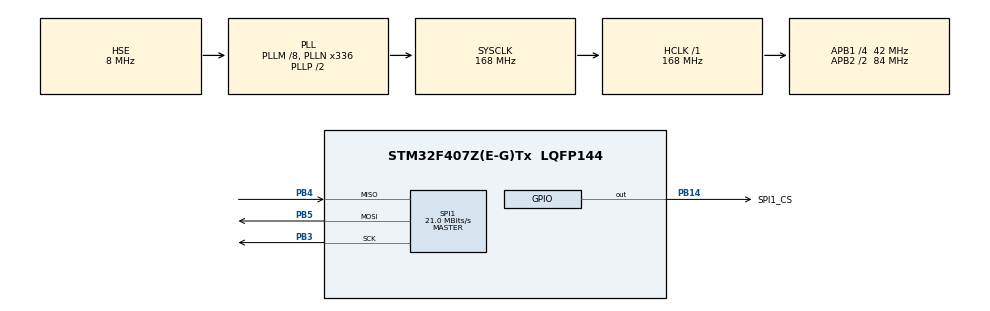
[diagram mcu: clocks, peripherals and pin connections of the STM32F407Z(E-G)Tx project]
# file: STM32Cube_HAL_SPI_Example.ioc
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Dma.Request0=SPI1_RX
Dma.Request1=SPI1_TX
Dma.SPI1_RX.0.Direction=DMA_PERIPH_TO_MEMORY
Dma.SPI1_RX.0.FIFOMode=DMA_FIFOMODE_DISABLE
Dma.SPI1_RX.0.Instance=DMA2_Stream0
Dma.SPI1_RX.0.MemDataAlignment=DMA_MDATAALIGN_BYTE
Dma.SPI1_RX.0.MemInc=DMA_MINC_ENABLE
Dma.SPI1_RX.0.Mode=DMA_NORMAL
Dma.SPI1_RX.0.PeriphDataAlignment=DMA_PDATAALIGN_BYTE
Dma.SPI1_RX.0.PeriphInc=DMA_PINC_DISABLE
Dma.SPI1_RX.0.Priority=DMA_PRIORITY_MEDIUM
Dma.SPI1_TX.1.Direction=DMA_MEMORY_TO_PERIPH
Dma.SPI1_TX.1.FIFOMode=DMA_FIFOMODE_DISABLE
Dma.SPI1_TX.1.Instance=DMA2_Stream3
Dma.SPI1_TX.1.MemDataAlignment=DMA_MDATAALIGN_BYTE
Dma.SPI1_TX.1.MemInc=DMA_MINC_ENABLE
Dma.SPI1_TX.1.Mode=DMA_NORMAL
Dma.SPI1_TX.1.PeriphDataAlignment=DMA_PDATAALIGN_BYTE
Dma.SPI1_TX.1.PeriphInc=DMA_PINC_DISABLE
Dma.SPI1_TX.1.Priority=DMA_PRIORITY_MEDIUM
Mcu.Family=STM32F4
Mcu.Name=STM32F407Z(E-G)Tx
Mcu.Package=LQFP144
NVIC.DMA2_Stream0_IRQn=true\:0\:0\:false\:true\:true\:2\:false
NVIC.DMA2_Stream3_IRQn=true\:0\:0\:false\:true\:true\:3\:false
NVIC.PriorityGroup=NVIC_PRIORITYGROUP_4
NVIC.SPI1_IRQn=true\:0\:0\:false\:true\:true\:1\:true
PB14.GPIO_Label=SPI1_CS
PB14.GPIO_PuPd=GPIO_PULLUP
PB14.GPIO_Speed=GPIO_SPEED_FREQ_VERY_HIGH
PB14.PinState=GPIO_PIN_SET
PB14.Signal=GPIO_Output
PB3.Mode=Full_Duplex_Master
PB3.Signal=SPI1_SCK
PB4.Mode=Full_Duplex_Master
PB4.Signal=SPI1_MISO
PB5.Mode=Full_Duplex_Master
PB5.Signal=SPI1_MOSI
PH0-OSC_IN.Mode=HSE-External-Oscillator
PH0-OSC_IN.Signal=RCC_OSC_IN
PH1-OSC_OUT.Mode=HSE-External-Oscillator
PH1-OSC_OUT.Signal=RCC_OSC_OUT
ProjectManager.HeapSize=0x200
ProjectManager.StackSize=0x400
ProjectManager.TargetToolchain=MDK-ARM V5
RCC.48MHZClocksFreq_Value=84000000
RCC.AHBFreq_Value=168000000
RCC.APB1CLKDivider=RCC_HCLK_DIV4
RCC.APB1Freq_Value=42000000
RCC.APB1TimFreq_Value=84000000
RCC.APB2CLKDivider=RCC_HCLK_DIV2
RCC.APB2Freq_Value=84000000
RCC.APB2TimFreq_Value=168000000
RCC.CortexFreq_Value=168000000
RCC.HCLKFreq_Value=168000000
RCC.HSE_VALUE=8000000
RCC.HSI_VALUE=16000000
RCC.LSE_VALUE=32768
RCC.PLLM=8
RCC.PLLN=336
RCC.PLLSourceVirtual=RCC_PLLSOURCE_HSE
RCC.SYSCLKFreq_VALUE=168000000
RCC.SYSCLKSource=RCC_SYSCLKSOURCE_PLLCLK
RCC.VCOOutputFreq_Value=336000000
SPI1.BaudRatePrescaler=SPI_BAUDRATEPRESCALER_4
SPI1.CalculateBaudRate=21.0 MBits/s
SPI1.Direction=SPI_DIRECTION_2LINES
SPI1.Mode=SPI_MODE_MASTER
SPI1.VirtualType=VM_MASTER
board=STM32Cube_HAL_SPI_Example

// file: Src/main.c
/**
  ******************************************************************************
  * File Name          : main.c
  * Description        : Main program body
  ******************************************************************************
  ** This notice applies to any and all portions of this file
  * that are not between comment pairs USER CODE BEGIN and
  * USER CODE END. Other portions of this file, whether
  * inserted by the user or by software development tools
  * are owned by their respective copyright owners.
  *
  * COPYRIGHT(c) 2018 STMicroelectronics
  *
  * Redistribution and use in source and binary forms, with or without modification,
  * are permitted provided that the following conditions are met:
  *   1. Redistributions of source code must retain the above copyright notice,
  *      this list of conditions and the following disclaimer.
  *   2. Redistributions in binary form must reproduce the above copyright notice,
  *      this list of conditions and the following disclaimer in the documentation
  *      and/or other materials provided with the distribution.
  *   3. Neither the name of STMicroelectronics nor the names of its contributors
  *      may be used to endorse or promote products derived from this software
  *      without specific prior written permission.
  *
  * THIS SOFTWARE IS PROVIDED BY THE COPYRIGHT HOLDERS AND CONTRIBUTORS "AS IS"
  * AND ANY EXPRESS OR IMPLIED WARRANTIES, INCLUDING, BUT NOT LIMITED TO, THE
  * IMPLIED WARRANTIES OF MERCHANTABILITY AND FITNESS FOR A PARTICULAR PURPOSE ARE
  * DISCLAIMED. IN NO EVENT SHALL THE COPYRIGHT HOLDER OR CONTRIBUTORS BE LIABLE
  * FOR ANY DIRECT, INDIRECT, INCIDENTAL, SPECIAL, EXEMPLARY, OR CONSEQUENTIAL
  * DAMAGES (INCLUDING, BUT NOT LIMITED TO, PROCUREMENT OF SUBSTITUTE GOODS OR
  * SERVICES; LOSS OF USE, DATA, OR PROFITS; OR BUSINESS INTERRUPTION) HOWEVER
  * CAUSED AND ON ANY THEORY OF LIABILITY, WHETHER IN CONTRACT, STRICT LIABILITY,
  * OR TORT (INCLUDING NEGLIGENCE OR OTHERWISE) ARISING IN ANY WAY OUT OF THE USE
  * OF THIS SOFTWARE, EVEN IF ADVISED OF THE POSSIBILITY OF SUCH DAMAGE.
  *
  ******************************************************************************
  */

#include "main.h"
#include "stm32f4xx_hal.h"
#include "dma.h"
#include "spi.h"
#include "gpio.h"

/* USER CODE BEGIN Includes */
#include <string.h>
/* USER CODE END Includes */

/* USER CODE BEGIN PV */
/* Private variables ---------------------------------------------------------*/
static uint8_t spi1TxBuff[5] = {0xAB};
static uint8_t spi1RxBuff[5] = {0};
static uint8_t dataBuff[5]   = {0};
/* USER CODE END PV */

void SystemClock_Config(void);
static void MX_NVIC_Init(void);

/* USER CODE BEGIN PFP */
/* Private function prototypes -----------------------------------------------*/

/* USER CODE END PFP */

int main(void)
{

  /* MCU Configuration----------------------------------------------------------*/

  /* Reset of all peripherals, Initializes the Flash interface and the Systick. */
  HAL_Init();

  /* Configure the system clock */
  SystemClock_Config();

  /* Initialize all configured peripherals */
  MX_GPIO_Init();
  MX_DMA_Init();
  MX_SPI1_Init();

  /* Initialize interrupts */
  MX_NVIC_Init();

  /* USER CODE BEGIN 2 */
  HAL_GPIO_WritePin(SPI1_CS_GPIO_Port, SPI1_CS_Pin, GPIO_PIN_RESET);
  HAL_SPI_TransmitReceive_DMA(&hspi1, spi1TxBuff, spi1RxBuff, sizeof(spi1TxBuff));
  /* USER CODE END 2 */

  /* Infinite loop */
  while (1)
  {

  }

}

/** System Clock Configuration
*/
void SystemClock_Config(void)
{

  RCC_OscInitTypeDef RCC_OscInitStruct;
  RCC_ClkInitTypeDef RCC_ClkInitStruct;

    /**Configure the main internal regulator output voltage
    */
  __HAL_RCC_PWR_CLK_ENABLE();

  __HAL_PWR_VOLTAGESCALING_CONFIG(PWR_REGULATOR_VOLTAGE_SCALE1);

    /**Initializes the CPU, AHB and APB busses clocks
    */
  RCC_OscInitStruct.OscillatorType = RCC_OSCILLATORTYPE_HSE;
  RCC_OscInitStruct.HSEState = RCC_HSE_ON;
  RCC_OscInitStruct.PLL.PLLState = RCC_PLL_ON;
  RCC_OscInitStruct.PLL.PLLSource = RCC_PLLSOURCE_HSE;
  RCC_OscInitStruct.PLL.PLLM = 8;
  RCC_OscInitStruct.PLL.PLLN = 336;
  RCC_OscInitStruct.PLL.PLLP = RCC_PLLP_DIV2;
  RCC_OscInitStruct.PLL.PLLQ = 4;
  if (HAL_RCC_OscConfig(&RCC_OscInitStruct) != HAL_OK)
  {
    _Error_Handler(__FILE__, __LINE__);
  }

    /**Initializes the CPU, AHB and APB busses clocks
    */
  RCC_ClkInitStruct.ClockType = RCC_CLOCKTYPE_HCLK|RCC_CLOCKTYPE_SYSCLK
                              |RCC_CLOCKTYPE_PCLK1|RCC_CLOCKTYPE_PCLK2;
  RCC_ClkInitStruct.SYSCLKSource = RCC_SYSCLKSOURCE_PLLCLK;
  RCC_ClkInitStruct.AHBCLKDivider = RCC_SYSCLK_DIV1;
  RCC_ClkInitStruct.APB1CLKDivider = RCC_HCLK_DIV4;
  RCC_ClkInitStruct.APB2CLKDivider = RCC_HCLK_DIV2;

  if (HAL_RCC_ClockConfig(&RCC_ClkInitStruct, FLASH_LATENCY_5) != HAL_OK)
  {
    _Error_Handler(__FILE__, __LINE__);
  }

    /**Configure the Systick interrupt time
    */
  HAL_SYSTICK_Config(HAL_RCC_GetHCLKFreq()/1000);

    /**Configure the Systick
    */
  HAL_SYSTICK_CLKSourceConfig(SYSTICK_CLKSOURCE_HCLK);

  /* SysTick_IRQn interrupt configuration */
  HAL_NVIC_SetPriority(SysTick_IRQn, 0, 0);
}

/** NVIC Configuration
*/
static void MX_NVIC_Init(void)
{
  /* SPI1_IRQn interrupt configuration */
  HAL_NVIC_SetPriority(SPI1_IRQn, 0, 0);
  HAL_NVIC_EnableIRQ(SPI1_IRQn);
  /* DMA2_Stream0_IRQn interrupt configuration */
  HAL_NVIC_SetPriority(DMA2_Stream0_IRQn, 0, 0);
  HAL_NVIC_EnableIRQ(DMA2_Stream0_IRQn);
  /* DMA2_Stream3_IRQn interrupt configuration */
  HAL_NVIC_SetPriority(DMA2_Stream3_IRQn, 0, 0);
  HAL_NVIC_EnableIRQ(DMA2_Stream3_IRQn);
}

/* USER CODE BEGIN 4 */
void HAL_SPI_TxRxCpltCallback(SPI_HandleTypeDef *hspi)
{
  if(hspi->Instance == SPI1)
  {
    HAL_GPIO_WritePin(SPI1_CS_GPIO_Port, SPI1_CS_Pin, GPIO_PIN_SET);
    memcpy(dataBuff, spi1RxBuff, sizeof(spi1RxBuff));
  }
}
/* USER CODE END 4 */

void _Error_Handler(char * file, int line)
{
  while(1)
  {
  }
}

/************************ (C) COPYRIGHT STMicroelectronics *****END OF FILE****/
